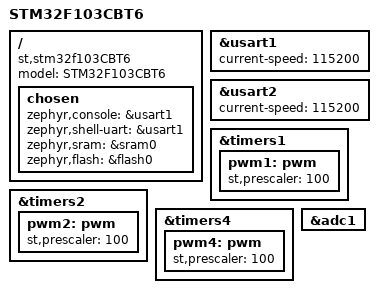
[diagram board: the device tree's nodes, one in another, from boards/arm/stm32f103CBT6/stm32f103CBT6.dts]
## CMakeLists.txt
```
# Find Zephyr. This also loads Zephyr's build system.
cmake_minimum_required(VERSION 3.13.1)

SET(BOARD_ROOT ${BOARD_ROOT} /Users/liuke/Desktop/internship/zephyr/app/)

find_package(Zephyr)
project(my_zephyr_app)

# Add your source file to the "app" target. This must come after
# find_package(Zephyr) which defines the target.
target_sources(app PRIVATE src/BT.c)
target_sources(app PRIVATE src/function.c)
target_sources(app PRIVATE src/main.c)

# message(INFO "linker is ${LINKER_SCRIPT}" )
```

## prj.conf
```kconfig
CONFIG_GPIO=y
CONFIG_SERIAL=y
CONFIG_PWM=y
CONFIG_ADC=y
CONFIG_UART_INTERRUPT_DRIVEN=y
CONFIG_RING_BUFFER=y
CONFIG_UART_CONSOLE_ON_DEV_NAME="UART_1"
```

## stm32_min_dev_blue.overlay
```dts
&usart2 {
	status = "okay";
};

&timers4 {
	status = "okay";

	pwm4: pwm {
		status = "okay";
		st,prescaler = <1000>;
	};
};
```

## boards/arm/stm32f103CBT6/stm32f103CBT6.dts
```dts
/*
 * Copyright (c) 2017, embedjournal.com
 *
 * SPDX-License-Identifier: Apache-2.0
 */

/dts-v1/;
#include <st/f1/stm32f103Xb.dtsi>

/ {
	model = "STM32F103CBT6";
	compatible = "st,stm32f103CBT6", "st,stm32f103cb";

	chosen {
		zephyr,console = &usart1;
		zephyr,shell-uart = &usart1;
		zephyr,sram = &sram0;
		zephyr,flash = &flash0;
	};
};


&usart1 {
	current-speed = <115200>;
	status = "okay";
};

&usart2 {
	current-speed = <115200>;
	status = "okay";
};

&timers1 {
	status = "okay";

	pwm1: pwm {
		status = "okay";
		st,prescaler = <100>;
	};
};

&timers2 {
	status = "okay";

	pwm2: pwm {
		status = "okay";
		st,prescaler = <100>;
	};
};

&timers4 {
	status = "okay";

	pwm4: pwm {
		status = "okay";
		st,prescaler = <100>;
	};
};

&adc1 {
	status = "okay";
};
```

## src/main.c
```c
#include "function.h"

void main(void)
{

	printk("here\n");
	// bool led_is_on = true;
	int ret;

	/* initiate system, bluetooth and ring buf */
	ret = system_init();
	if(ret < 0){
		return;
	}

	// while(1){
	// 	uint8_t* msg = "AT:MAC?\r\n";
	// 	uart_poll_out_multi(dev_UART2, msg, 9);
	// 	k_msleep(1000);
	// 	printk_buf_str(buf);

	// }
	
	/* wait for bluetooth to connect */
	while(!bluetooth_is_connected()){
		printk("waiting for bluetooth to connect\n");
		k_msleep(1000);
	}
	printk("bluetooth connected\n");
	k_msleep(5000);


	/* obtain voltage message */
	float voltage_result = get_voltage();
	if(voltage_result<0){
		return;
	}

	/* transmit voltage message */
	transmit_voltage_message((int)voltage_result);


	/* wait for message */
	uint8_t data[20];
	// uint8_t* msg = "AT:MAC?\r\n";

	int size;
	while(1){
		size = pull_one_message(data);
		if(size>0){
			break;
		}else{
			printk("waiting for data\n");
		}
		printk_buf_str(buf);
		k_msleep(5000);

	}

	/* set led power on */
	set_led_power_on();

	/* decode message */
	uint16_t period = 0;
	uint16_t pulse = 0;
	uint16_t duration = 0;
	uint16_t voltage = 0;

	if(size == VOLTAGE_MESSAGE_LENGTH){
		decode_voltage_message(data, &voltage);
	}else if(size == PWM_MESSAGE_LENGTH){
		decode_pwm_message(data, &period, &pulse, &duration);
	}

	/* set pwm to led */
	ret = set_pwm_to_led(period, pulse, duration);
	if(ret<0){
		printk("do not set pwm\n");
		return;
	}
}
```

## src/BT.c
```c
#include "BT.h"

struct device *dev;

uint8_t read_in_buf[MAX_LINE_LENGTH]={0};


struct read_in_buffer buf = {
	.buf = read_in_buf,
	.size = 0
};

struct ring_buf_container telegram_queue;



const struct uart_config cfg = {
	.baudrate = 115200,
	.parity = UART_CFG_PARITY_NONE,
	.stop_bits = UART_CFG_STOP_BITS_1,
	.data_bits = UART_CFG_DATA_BITS_8,
	.flow_ctrl = UART_CFG_FLOW_CTRL_NONE
};


int uart_fifo_init(void){
	uint8_t c;
	dev = device_get_binding("UART_2");
	if (dev == NULL) {
		printk("cannot find device\n");
		return -1;
	}
	if(uart_configure(dev, &cfg) != 0){
		printk("configure error\n");
	}
	printk("configure succuessfully\n");

	uart_irq_rx_disable(dev);
	uart_irq_tx_disable(dev);
		
	uart_irq_callback_set(dev, uart_fifo_callback);

	/* Drain the fifo */
	if (uart_irq_rx_ready(dev)) {
		while (uart_fifo_read(dev, &c, 1)) {
			;
		}
	}
	uart_irq_rx_enable(dev);

	/* Enable all interrupts unconditionally. Note that this is due
	 * to Zephyr issue #8393. This should be removed once the
	 * issue is fixed in upstream Zephyr.
	 */
	irq_unlock(0);

	return 0;

}

void printk_buf_hex(struct read_in_buffer buffer){
	printk("buffer content:");
	for(int i=0;i<buffer.size;i++){
		printk("0x%02x ",buffer.buf[i]);
	}
	printk("\n");
}

void printk_buf_str(struct read_in_buffer buffer){
	printk("buffer content:");
	for(int i=0;i<buffer.size;i++){
		if(buffer.buf[i]>32 && buffer.buf[i]<127){
			printk("%c",buffer.buf[i]);
		}
	}
	printk("\n");
}

void uart_fifo_callback(struct device *dev){
	while(uart_irq_update(dev) && uart_irq_is_pending(dev)){
		if (!uart_irq_rx_ready(dev)){
			continue;
		}
		else{
			buf.size += uart_fifo_read(dev, &buf.buf[buf.size], MAX_LINE_LENGTH);
			if (buf.size>=2 && buf.buf[buf.size-1]== 27 && buf.buf[buf.size-2]== 27){
				clear_voltage_buf();
				buf.buf[0] = 27;
				buf.buf[1] = 27;
				buf.size = 2;
			}
			if(buf.size>=2 && buf.buf[buf.size-1]==177 && buf.buf[buf.size-2]==177){
				int ret=ring_buf_put(&telegram_queue.rb,buf.buf,buf.size);
				printk("enqueue:%d\n",ret);
				clear_voltage_buf();
			}
		}

	}

	if(buf.size>MAX_LINE_LENGTH){
		printk("buf overfit\n");
		clear_voltage_buf();
	}
}


void clear_voltage_buf(void){
	buf.size = 0;
}


int is_telegram_correct(uint8_t *data, uint32_t size){
	// struct voltage_message msg;
	int len;
	uint8_t check_value;
	if (size == 11){
		len = data[2]*16*16+data[3];
		if (len != size){
			printk("voltage message size error\n");
			return -1;
		}
		check_value = data[2]*16*16+data[3]+data[4]*16*16+data[5]+data[6]*16*16+data[7];
		if(check_value == data[8]){
			return size;
		}else{
			printk("voltage message check value error\n");
		}
	}else if (size == 15){
		len = data[2]*16*16+data[3];
		if (len != size){
			printk("pwm message size error\n");
			return -1;
		}
		check_value = data[2]*16*16+data[3]+data[4]*16*16+data[5]+data[6]*16*16+data[7]+data[8]*16*16+data[9]+data[10]*16*16+data[11];
		if(check_value == data[12]){
			return size;
		}else{
			printk("pwm message check value error\n");
		}
	}
	return -1;
}


int pull_one_message(uint8_t *data){
	// uint8_t *ret_data;
	uint32_t size=0;
	while(!ring_buf_is_empty(&telegram_queue.rb)){
		// printk("try to get message\n");
		size+=ring_buf_get(&telegram_queue.rb,&data[size],1);
		// printk("size:%d\n",size);
		if (size>2 && data[size-1]==177 && data[size-2]==177){
			break;
		}
	}
	printk("data[size-1]:%d\n",data[size-1]);
	if (size>2 && data[size-1]==177 && data[size-2]==177){
		return is_telegram_correct(data,size);
	}else{
		printk("no complete message in queue\n");
		return -1;
	}
}


void uart_poll_out_multi(struct device *dev, unsigned char* str, int len){
	for (int i=0; i<len;i++){
		uart_poll_out(dev, *str++);
	}
}
```

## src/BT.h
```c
#ifndef __BT_H_
#define __BT_H_

#include <zephyr.h>
#include <device.h>
#include <sys/printk.h>
#include <drivers/uart.h>
#include <sys/ring_buffer.h>


#ifdef __cplusplus
extern "C" {
#endif

#define MY_RING_BUF_SIZE 64
#define MAX_LINE_LENGTH 128
#define VOLTAGE_MESSAGE_LENGTH 11
#define PWM_MESSAGE_LENGTH 15
#define SOF_CHAR 0xb1
#define EOF_CHAR 0x1b

struct voltage_message {
	/* data */
	uint16_t SOF;
	uint16_t len;
	uint16_t cmd;
	uint16_t data;
	uint8_t crc;
	uint16_t EOF;
};

struct pwm_message {
	/* data */
	uint16_t SOF;
	uint16_t len;
	uint16_t cmd;
	uint16_t period; //in unit of us
	uint16_t pulse;
	uint16_t duration;
	uint8_t crc;
	uint16_t EOF;
};

struct read_in_buffer {
	uint8_t *buf;
	int size;
};

struct ring_buf_container {
    struct ring_buf rb;
    uint8_t buffer[MY_RING_BUF_SIZE];

};

extern struct device *dev;
extern uint8_t read_in_buf[];
extern struct read_in_buffer buf;
extern struct ring_buf_container telegram_queue;


void uart_fifo_callback(struct device *dev);
int uart_fifo_init(void);
void printk_buf_hex(struct read_in_buffer buffer);
void printk_buf_str(struct read_in_buffer buffer);
int voltage_telegram_ready(struct read_in_buffer buffer);
void clear_voltage_buf(void);
int pull_one_message(uint8_t *data);
int is_telegram_correct(uint8_t *data, uint32_t size);
void uart_poll_out_multi(struct device *dev, unsigned char* str, int len);

#ifdef __cplusplus
}
#endif

#endif /* __BT_H_ */
```

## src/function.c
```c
#include "function.h"

struct device *dev_GPIOA;
struct device *dev_GPIOB;
struct device *dev_UART2;
struct device *dev_ADC1;

static const struct adc_channel_cfg adc_ch_cfg = {
	.gain  = ADC_GAIN_1,
	.reference = ADC_REF_INTERNAL,
	.acquisition_time = ADC_ACQ_TIME_DEFAULT,
	.channel_id = 1,
	.differential  = 0
};

uint16_t adc_buffer[100] = {0};

const struct adc_sequence sequence = {
	.options = NULL,
	.channels = BIT(1),
	.buffer = adc_buffer,
	.buffer_size = 10,
	.resolution = 12
};


/* system_init():
 * This function is used to intiate the whole system
 * This function will turn on system, bluetooth, ring buf and set bluetooth mode to slave
 */
int system_init(void){
    dev_GPIOA = device_get_binding("GPIOA");
    dev_GPIOB = device_get_binding("GPIOB");
    dev_UART2 = device_get_binding("UART_2");
    dev_ADC1 = device_get_binding("ADC_1");

    int ret;
	if (dev_GPIOB == NULL || dev_GPIOA == NULL || dev_UART2 == NULL || dev_ADC1 == NULL) {
		printk("cannnot find GPIOA or GPIOB or UART2 or ADC1\n");
		return -1;
	}

	/* set system on */
	ret = gpio_pin_configure(dev_GPIOB, 13, GPIO_OUTPUT_ACTIVE | FLAGS);
	if (ret < 0) {
		return -1;
	}
	ret = gpio_pin_set(dev_GPIOB, 13, 1);
	printk("system on status: %d\n", ret);
	
	/* set bluetooth working */
	ret = gpio_pin_configure(dev_GPIOA, 7, GPIO_OUTPUT_ACTIVE | FLAGS);
	if (ret < 0) {
		return -1;
	}
	ret = gpio_pin_set(dev_GPIOA, 7, 0);
	printk("bluetooth status:%d\n",ret);

	/* set bluetooth slave mode */
	ret = gpio_pin_configure(dev_GPIOA, 5, GPIO_OUTPUT_ACTIVE | FLAGS);
	if (ret < 0) {
		return -1;
	}
	ret = gpio_pin_set(dev_GPIOA, 5, 1);
	printk("bluetooth mode:%d\n",ret);
    return 0;

	/* initiate ring buf */
    ring_buf_init(&telegram_queue.rb, MY_RING_BUF_SIZE , telegram_queue.buffer);
	uart_fifo_init();

}

/* bluetooth_is_connected():
 * this function would check whether bluetooth is connected
 */
bool bluetooth_is_connected(void){
	if(dev_GPIOA == NULL){
		printk("not GPIOA found\n");
		return false;
	}
	int ret = gpio_pin_get(dev_GPIOA, 6);
	if(ret == 0){
		return true;
	}
	return false;
}



/* get_voltage():
 * This function will return the voltage from ADC_1, channel 1, which is PA1
 */
float get_voltage(void){
    int ret;
    float result = 0;
	ret = adc_channel_setup(dev_ADC1, &adc_ch_cfg);
	// printk("here2\n");
	if (ret != 0) {
		printk("Setting up of adc channel failed with code %d\n", ret);
		return -1;
	}
	if(adc_read(dev_ADC1,&sequence) < 0){
		printk("cannot read value\n");
        return -1;
	}else{
        // result = 
		result = adc_buffer[0]/4096.0*3300.0*2.0;
		// printk("result:%d\n",(int)result);
		printk("voltage:\n");
		PrintFloat(result);
		printk("mV\n");
	}
    return result;
}

/* transmit_voltage_message():
 * This function would transfer voltage data to telegraph format 
 * and send it through bluetooth.
 * Before using this function, you should check bluetooth is connected.
 */
void transmit_voltage_message(int voltage){
    struct voltage_message msg;
	compose_message(&msg,voltage);

	unsigned char voltage_buf[15]={0};
	voltage_message_format_convert(&msg,voltage_buf);
	uart_poll_out_multi(dev_UART2,voltage_buf, msg.len);
	printk("send out telegraph\n");
}


/* set_led_power_on():
 * This function would turn led power on 
 */
void set_led_power_on(void){
    int ret;
    ret = gpio_pin_configure(dev_GPIOB, 14, GPIO_OUTPUT_ACTIVE | FLAGS);
	if (ret < 0) {
		return;
	}
	ret = gpio_pin_set(dev_GPIOB, 14, 1);
	printk("led power on status: %d\n", ret);
}


/* PrintFloat():
 * This function would help to printk float data. 
 */

void PrintFloat(float value){
	int tmp,tmp1,tmp2,tmp3,tmp4,tmp5,tmp6;
	tmp = (int)value;
	tmp1=(int)((value-tmp)*10)%10;
	tmp2=(int)((value-tmp)*100)%10;
	tmp3=(int)((value-tmp)*1000)%10;
	tmp4=(int)((value-tmp)*10000)%10;
	tmp5=(int)((value-tmp)*100000)%10;
	tmp6=(int)((value-tmp)*1000000)%10;
	printk("%d.%d%d%d%d%d%d ",tmp,tmp1,tmp2,tmp3,tmp4,tmp5,tmp6);

}


/* decode_pwm_message():
 * This function will get period, pulse and duration from pointer data
 */ 
void decode_pwm_message(uint8_t* data, uint16_t *period,uint16_t *pulse, uint16_t *duration){
    printk("get a pwm message\n");
	*period = data[6]*16*16+data[7];
	*pulse = data[8]*16*16+data[9];
	*duration = data[10]*16*16+data[11];
    printk("period: %d, pulse: %d, duration: %d\n", *period, *pulse, *duration);
}


/* decode_voltage_message():
 * This function will get voltage from pointer data
 */ 
void decode_voltage_message(uint8_t* data, uint16_t *voltage){
    printk("get a voltage message\n");
	*voltage = data[6]*16*16+data[7];
	printk("voltage:%d\n", *voltage);
}



/* set_pwm_to_led():
 * This function would set pwm with periof and pulse to T4C1,T4C2,T2C3,T2C4
 */ 
int set_pwm_to_led(uint16_t period, uint16_t pulse, uint16_t duration){
    int ret;
    const char* label4 = "PWM_4";
	struct device *dev_pwm4 = device_get_binding(label4);
	if (!dev_pwm4) {
	    printk("Error: didn't find %s device\n", label4);
		return -1;
	}
	printk("%s correct\n", label4);

	// uint64_t cycles;
	// ret = pwm_get_cycles_per_sec(dev_pwm4,1, &cycles);
	// printk("clock rate: %lld\n",cycles);
	ret = pwm_pin_set_usec(dev_pwm4,1, period, pulse, PWM_FLAGS);
	if(ret < 0){
		printk("error %d\n",ret);
        return -1;
	}
	printk("set %s,channel 1, successfully\n",label4);
	ret = pwm_pin_set_usec(dev_pwm4,2, period, pulse, PWM_FLAGS);
	if(ret < 0){
		printk("error %d\n",ret);
        return -1;
	}
	printk("set %s,channel 2, successfully\n",label4);

    const char* label2 = "PWM_2";
	struct device *dev_pwm2 = device_get_binding(label2);
	if (!dev_pwm2) {
		printk("Error: didn't find %s device\n", label2);
		return -1;
	}
	printk("%s correct\n", label2);

	ret = pwm_pin_set_usec(dev_pwm2,3, period, pulse, PWM_FLAGS);
	if(ret < 0){
		printk("error %d\n",ret);
        return -1;
	}
	printk("set %s,channel 3, successfully\n",label2);
	ret = pwm_pin_set_usec(dev_pwm2,4, period, pulse, PWM_FLAGS);
	if(ret < 0){
		printk("error %d\n",ret);
        return -1;
	}
	printk("set %s,channel 4, successfully\n",label2);
    return 0;
}

/* voltage_message_format_convert():
 * This function would convert data in msg to buf, which can be transmitted by bluetooth
 */ 
void voltage_message_format_convert(struct voltage_message *msg, unsigned char* buf){
	*buf = (unsigned char)((msg->SOF >> 8) & 0xFF);
	*(buf+1) = (unsigned char)((msg->SOF) & 0xFF);
	*(buf+2) = (unsigned char)((msg->len >> 8) & 0xFF);
	*(buf+3) = (unsigned char)((msg->len) & 0xFF);
	*(buf+4) = (unsigned char)((msg->cmd >> 8) & 0xFF);
	*(buf+5) = (unsigned char)((msg->cmd) & 0xFF);
	*(buf+6) = (unsigned char)((msg->data >> 8) & 0xFF);
	*(buf+7) = (unsigned char)((msg->data) & 0xFF);
	*(buf+8) = (unsigned char)(msg->crc);
	*(buf+9) = (unsigned char)((msg->EOF >> 8) & 0xFF);
	*(buf+10) = (unsigned char)((msg->EOF) & 0xFF);

	printk("buf[0]:0x%02x \n",buf[0]);
}


/* compose_message():
 * This function would compose a telegram that contain voltage information
 */
int compose_message(struct voltage_message *msg, uint16_t voltage){
	msg->SOF = 0xb1b1;
	msg->len = 11;
	msg->cmd = 0;
	msg->data = voltage;
	msg->crc = msg->cmd+msg->data+msg->len;
	msg->EOF = 0x1b1b;
	printk("msg->SOF:%d\n",msg->SOF);
	return 0;
}

/* send_inst_to_bluetooth():
 * This function will send a message to bluetooth and printk the result which is stored in ring_buf
 */

int send_inst_to_bluetooth(uint8_t *msg,int size){
	if(dev_UART2 != NULL){
		return -1;
	}
	uart_poll_out_multi(dev_UART2, msg, size);
	k_msleep(100);
	printk_buf_str(buf);
	return 0;
}
```

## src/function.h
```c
#ifndef __FUNCTION_H_
#define __FUNCTION_H_

#ifdef __cplusplus
extern "C" {
#endif

#include <drivers/gpio.h>
#include <drivers/adc.h>
#include <drivers/pwm.h>
#include "BT.h"

#define FLAGS	0
#define PWM_FLAGS	0

extern struct device *dev_GPIOA;
extern struct device *dev_GPIOB;
extern struct device *dev_UART2; 
extern struct device *dev_ADC1;

extern uint16_t adc_buffer[];

extern const struct adc_sequence sequence;



void PrintFloat(float value);
int compose_message(struct voltage_message *msg, uint16_t voltage);
void voltage_message_format_convert(struct voltage_message *msg, uint8_t *buf);
int system_init(void);
bool bluetooth_is_connected(void);
float get_voltage(void);
void transmit_voltage_message(int voltage);
void set_led_power_on(void);
void decode_pwm_message(uint8_t* data, uint16_t *period,uint16_t *pulse, uint16_t *duration);
void decode_voltage_message(uint8_t* data, uint16_t *voltage);
int set_pwm_to_led(uint16_t period, uint16_t pulse, uint16_t duration);
int send_inst_to_bluetooth(uint8_t *msg,int size);




#ifdef __cplusplus
}
#endif

#endif /* __FUNCTION_H_ */
```

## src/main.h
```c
#ifndef __MAIN_H_
#define __MAIN_H_

#ifdef __cplusplus
extern "C" {
#endif

#include <drivers/adc.h>
#include <sys/printk.h>
#include <device.h>

void PrintFloat(float value);
int compose_message(struct voltage_message *msg, uint16_t voltage);
void voltage_message_format_convert(struct voltage_message *msg, uint8_t *buf);

static const struct adc_channel_cfg adc_ch_cfg = {
	.gain  = ADC_GAIN_1,
	.reference = ADC_REF_INTERNAL,
	.acquisition_time = ADC_ACQ_TIME_DEFAULT,
	.channel_id = 1,
	.differential  = 0
};

uint16_t buffer[100];

const struct adc_sequence sequence = {
	.options = NULL,
	.channels = BIT(1),
	.buffer = buffer,
	.buffer_size = 10,
	.resolution = 12
};

// struct voltage_message {
// 	/* data */
// 	uint16_t SOF;
// 	uint16_t len;
// 	uint16_t cmd;
// 	uint16_t data;
// 	uint8_t crc;
// 	uint16_t EOF;
// };



#ifdef __cplusplus
}
#endif

#endif /* __MAIN_H_ */
```
